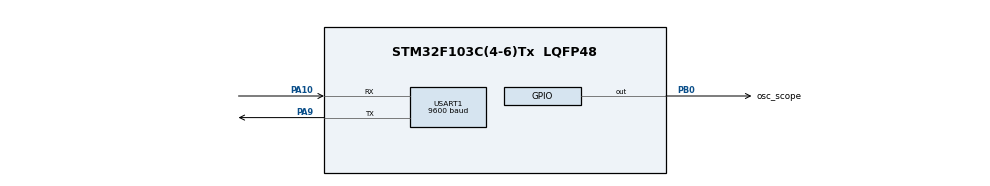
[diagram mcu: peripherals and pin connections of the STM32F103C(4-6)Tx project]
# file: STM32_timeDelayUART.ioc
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Mcu.Family=STM32F1
Mcu.Name=STM32F103C(4-6)Tx
Mcu.Package=LQFP48
NVIC.PriorityGroup=NVIC_PRIORITYGROUP_4
PA10.Mode=Asynchronous
PA10.Signal=USART1_RX
PA9.Mode=Asynchronous
PA9.Signal=USART1_TX
PB0.GPIO_Label=osc_scope
PB0.PinState=GPIO_PIN_SET
PB0.Signal=GPIO_Output
PD0-OSC_IN.Mode=HSE-External-Oscillator
PD0-OSC_IN.Signal=RCC_OSC_IN
PD1-OSC_OUT.Mode=HSE-External-Oscillator
PD1-OSC_OUT.Signal=RCC_OSC_OUT
ProjectManager.HeapSize=0x200
ProjectManager.StackSize=0x400
ProjectManager.TargetToolchain=STM32CubeIDE
RCC.APB1Freq_Value=8000000
RCC.APB2Freq_Value=8000000
USART1.BaudRate=9600
USART1.VirtualMode=VM_ASYNC
VP_SYS_VS_ND.Mode=No_Debug
board=custom

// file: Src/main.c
/* USER CODE BEGIN Header */
/**
  ******************************************************************************
  * @file           : main.c
  * @brief          : Main program body
  ******************************************************************************
  * @attention
  *
  * <h2><center>&copy; Copyright (c) 2020 STMicroelectronics.
  * All rights reserved.</center></h2>
  *
  * This software component is licensed by ST under BSD 3-Clause license,
  * the "License"; You may not use this file except in compliance with the
  * License. You may obtain a copy of the License at:
  *                        opensource.org/licenses/BSD-3-Clause
  *
  ******************************************************************************
  */
/* USER CODE END Header */

#include "main.h"

UART_HandleTypeDef huart1;

void SystemClock_Config(void);
static void MX_GPIO_Init(void);
static void MX_USART1_UART_Init(void);

/* USER CODE BEGIN 0 */
void flash()
{
	while(1){
		HAL_GPIO_WritePin(osc_scope_GPIO_Port, osc_scope_Pin, GPIO_PIN_SET);
		HAL_Delay(5);
		HAL_GPIO_WritePin(osc_scope_GPIO_Port, osc_scope_Pin, GPIO_PIN_RESET);
		HAL_Delay(5);
	}
}
void nops()
{
	while(1){
		HAL_GPIO_WritePin(osc_scope_GPIO_Port, osc_scope_Pin, GPIO_PIN_SET);
		__NOP();
		__NOP();
		__NOP();
		__NOP();
		__NOP();
		__NOP();
		__NOP();

		__NOP();
				__NOP();
				__NOP();
				__NOP();
				__NOP();
				__NOP();
				__NOP();
		HAL_GPIO_WritePin(osc_scope_GPIO_Port, osc_scope_Pin, GPIO_PIN_RESET);
		__NOP();
		__NOP();
		__NOP();
		__NOP();
		__NOP();
		__NOP();
		__NOP();

		__NOP();
				__NOP();
				__NOP();
				__NOP();
				__NOP();
				__NOP();
				__NOP();

	}
}
/* USER CODE END 0 */

int main(void)
{

  /* MCU Configuration--------------------------------------------------------*/

  /* Reset of all peripherals, Initializes the Flash interface and the Systick. */
  HAL_Init();

  /* Configure the system clock */
  SystemClock_Config();

  /* Initialize all configured peripherals */
  MX_GPIO_Init();
  MX_USART1_UART_Init();
  /* USER CODE BEGIN 2 */
  //__HAL_UART_ENABLE_IT(&huart1,UART_IT_TC);

  char buff[] = {'2','4','.','0','0'};

  if(HAL_UART_Transmit(&huart1, (uint8_t*)"500ms\r\n", 7, 5000)!= HAL_OK)
  {
	Error_Handler();
  }
  nops();

  /* USER CODE END 2 */

  /* Infinite loop */
  while (1)
  {

  }
}

void SystemClock_Config(void)
{
  RCC_OscInitTypeDef RCC_OscInitStruct = {0};
  RCC_ClkInitTypeDef RCC_ClkInitStruct = {0};

  /** Initializes the CPU, AHB and APB busses clocks
  */
  RCC_OscInitStruct.OscillatorType = RCC_OSCILLATORTYPE_HSI;
  RCC_OscInitStruct.HSIState = RCC_HSI_ON;
  RCC_OscInitStruct.HSICalibrationValue = RCC_HSICALIBRATION_DEFAULT;
  RCC_OscInitStruct.PLL.PLLState = RCC_PLL_NONE;
  if (HAL_RCC_OscConfig(&RCC_OscInitStruct) != HAL_OK)
  {
    Error_Handler();
  }
  /** Initializes the CPU, AHB and APB busses clocks
  */
  RCC_ClkInitStruct.ClockType = RCC_CLOCKTYPE_HCLK|RCC_CLOCKTYPE_SYSCLK
                              |RCC_CLOCKTYPE_PCLK1|RCC_CLOCKTYPE_PCLK2;
  RCC_ClkInitStruct.SYSCLKSource = RCC_SYSCLKSOURCE_HSI;
  RCC_ClkInitStruct.AHBCLKDivider = RCC_SYSCLK_DIV1;
  RCC_ClkInitStruct.APB1CLKDivider = RCC_HCLK_DIV1;
  RCC_ClkInitStruct.APB2CLKDivider = RCC_HCLK_DIV1;

  if (HAL_RCC_ClockConfig(&RCC_ClkInitStruct, FLASH_LATENCY_0) != HAL_OK)
  {
    Error_Handler();
  }
}

static void MX_USART1_UART_Init(void)
{

  huart1.Instance = USART1;
  huart1.Init.BaudRate = 9600;
  huart1.Init.WordLength = UART_WORDLENGTH_8B;
  huart1.Init.StopBits = UART_STOPBITS_1;
  huart1.Init.Parity = UART_PARITY_NONE;
  huart1.Init.Mode = UART_MODE_TX_RX;
  huart1.Init.HwFlowCtl = UART_HWCONTROL_NONE;
  huart1.Init.OverSampling = UART_OVERSAMPLING_16;
  if (HAL_UART_Init(&huart1) != HAL_OK)
  {
    Error_Handler();
  }

}

static void MX_GPIO_Init(void)
{
  GPIO_InitTypeDef GPIO_InitStruct = {0};

  /* GPIO Ports Clock Enable */
  __HAL_RCC_GPIOD_CLK_ENABLE();
  __HAL_RCC_GPIOB_CLK_ENABLE();
  __HAL_RCC_GPIOA_CLK_ENABLE();

  /*Configure GPIO pin Output Level */
  HAL_GPIO_WritePin(osc_scope_GPIO_Port, osc_scope_Pin, GPIO_PIN_SET);

  /*Configure GPIO pin : osc_scope_Pin */
  GPIO_InitStruct.Pin = osc_scope_Pin;
  GPIO_InitStruct.Mode = GPIO_MODE_OUTPUT_PP;
  GPIO_InitStruct.Pull = GPIO_NOPULL;
  GPIO_InitStruct.Speed = GPIO_SPEED_FREQ_LOW;
  HAL_GPIO_Init(osc_scope_GPIO_Port, &GPIO_InitStruct);

}

void Error_Handler(void)
{
}

/************************ (C) COPYRIGHT STMicroelectronics *****END OF FILE****/
